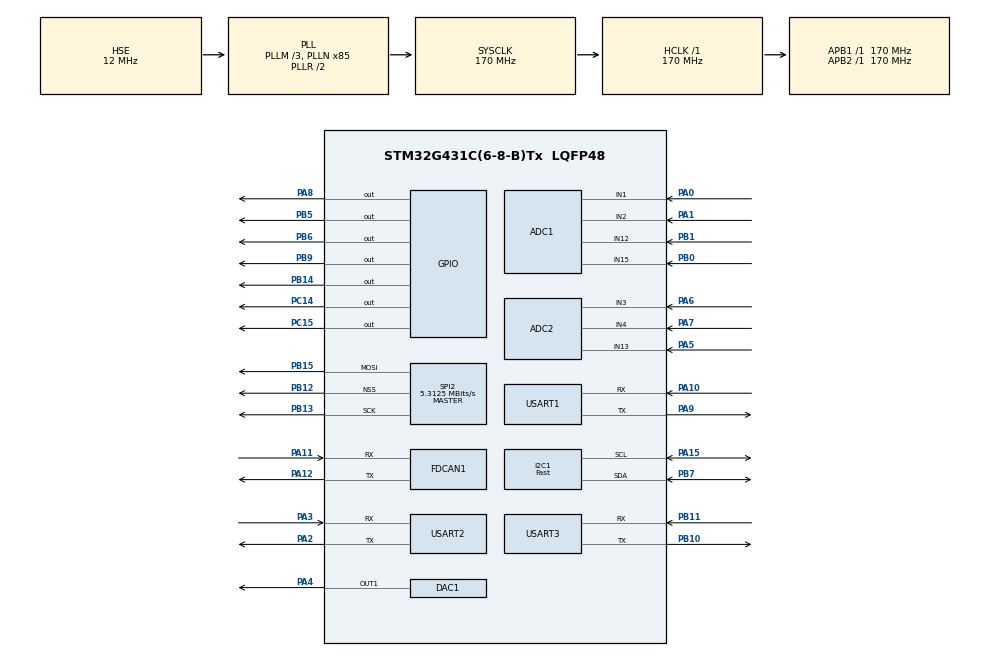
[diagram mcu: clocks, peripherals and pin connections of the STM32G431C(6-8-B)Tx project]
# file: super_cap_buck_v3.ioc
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ADC1.Channel-0\#ChannelRegularConversion=ADC_CHANNEL_1
ADC1.Channel-1\#ChannelRegularConversion=ADC_CHANNEL_2
ADC1.Channel-2\#ChannelRegularConversion=ADC_CHANNEL_12
ADC1.Channel-3\#ChannelRegularConversion=ADC_CHANNEL_15
ADC1.Channel-4\#ChannelRegularConversion=ADC_CHANNEL_TEMPSENSOR_ADC1
ADC1.ClockPrescaler=ADC_CLOCK_ASYNC_DIV6
ADC1.ContinuousConvMode=ENABLE
ADC1.DMAContinuousRequests=ENABLE
ADC1.DiscontinuousConvMode=DISABLE
ADC1.EOCSelection=ADC_EOC_SEQ_CONV
ADC1.EnableInjectedConversion=DISABLE
ADC1.GainCompensation=0
ADC1.NbrOfConversion=5
ADC1.NbrOfConversionFlag=1
ADC1.OffsetNumber-0\#ChannelRegularConversion=ADC_OFFSET_NONE
ADC1.OffsetNumber-1\#ChannelRegularConversion=ADC_OFFSET_NONE
ADC1.OffsetNumber-2\#ChannelRegularConversion=ADC_OFFSET_NONE
ADC1.OffsetNumber-3\#ChannelRegularConversion=ADC_OFFSET_NONE
ADC1.OffsetNumber-4\#ChannelRegularConversion=ADC_OFFSET_NONE
ADC1.OversamplingMode=ENABLE
ADC1.Rank-0\#ChannelRegularConversion=1
ADC1.Rank-1\#ChannelRegularConversion=2
ADC1.Rank-2\#ChannelRegularConversion=3
ADC1.Rank-3\#ChannelRegularConversion=4
ADC1.Rank-4\#ChannelRegularConversion=5
ADC1.Ratio=ADC_OVERSAMPLING_RATIO_256
ADC1.RightBitShift=ADC_RIGHTBITSHIFT_4
ADC1.SamplingTime-0\#ChannelRegularConversion=ADC_SAMPLETIME_3CYCLES_5
ADC1.SamplingTime-1\#ChannelRegularConversion=ADC_SAMPLETIME_3CYCLES_5
ADC1.SamplingTime-2\#ChannelRegularConversion=ADC_SAMPLETIME_3CYCLES_5
ADC1.SamplingTime-3\#ChannelRegularConversion=ADC_SAMPLETIME_3CYCLES_5
ADC1.SamplingTime-4\#ChannelRegularConversion=ADC_SAMPLETIME_92CYCLES_5
ADC1.master=1
ADC2.Channel-0\#ChannelRegularConversion=ADC_CHANNEL_13
ADC2.Channel-1\#ChannelRegularConversion=ADC_CHANNEL_3
ADC2.Channel-2\#ChannelRegularConversion=ADC_CHANNEL_4
ADC2.ClockPrescaler=ADC_CLOCK_ASYNC_DIV6
ADC2.ContinuousConvMode=ENABLE
ADC2.DMAContinuousRequests=ENABLE
ADC2.EOCSelection=ADC_EOC_SEQ_CONV
ADC2.EnableAnalogWatchDog1=false
ADC2.EnableInjectedConversion=DISABLE
ADC2.NbrOfConversion=3
ADC2.NbrOfConversionFlag=1
ADC2.OffsetNumber-0\#ChannelRegularConversion=ADC_OFFSET_NONE
ADC2.OffsetNumber-1\#ChannelRegularConversion=ADC_OFFSET_NONE
ADC2.OffsetNumber-2\#ChannelRegularConversion=ADC_OFFSET_NONE
ADC2.OversamplingMode=ENABLE
ADC2.Rank-0\#ChannelRegularConversion=1
ADC2.Rank-1\#ChannelRegularConversion=2
ADC2.Rank-2\#ChannelRegularConversion=3
ADC2.Ratio=ADC_OVERSAMPLING_RATIO_256
ADC2.RightBitShift=ADC_RIGHTBITSHIFT_4
ADC2.SamplingTime-0\#ChannelRegularConversion=ADC_SAMPLETIME_3CYCLES_5
ADC2.SamplingTime-1\#ChannelRegularConversion=ADC_SAMPLETIME_3CYCLES_5
ADC2.SamplingTime-2\#ChannelRegularConversion=ADC_SAMPLETIME_3CYCLES_5
DAC1.DAC_Trigger_OUT1-DAC_OUT1=DAC_TRIGGER_SOFTWARE
Dma.ADC1.0.Direction=DMA_PERIPH_TO_MEMORY
Dma.ADC1.0.EventEnable=DISABLE
Dma.ADC1.0.Instance=DMA1_Channel1
Dma.ADC1.0.MemDataAlignment=DMA_MDATAALIGN_WORD
Dma.ADC1.0.MemInc=DMA_MINC_ENABLE
Dma.ADC1.0.Mode=DMA_CIRCULAR
Dma.ADC1.0.PeriphDataAlignment=DMA_PDATAALIGN_WORD
Dma.ADC1.0.PeriphInc=DMA_PINC_DISABLE
Dma.ADC1.0.Polarity=HAL_DMAMUX_REQ_GEN_RISING
Dma.ADC1.0.Priority=DMA_PRIORITY_HIGH
Dma.ADC1.0.RequestNumber=1
Dma.ADC1.0.SignalID=NONE
Dma.ADC1.0.SyncEnable=DISABLE
Dma.ADC1.0.SyncPolarity=HAL_DMAMUX_SYNC_NO_EVENT
Dma.ADC1.0.SyncRequestNumber=1
Dma.ADC1.0.SyncSignalID=NONE
Dma.ADC2.1.Direction=DMA_PERIPH_TO_MEMORY
Dma.ADC2.1.EventEnable=DISABLE
Dma.ADC2.1.Instance=DMA1_Channel3
Dma.ADC2.1.MemDataAlignment=DMA_MDATAALIGN_WORD
Dma.ADC2.1.MemInc=DMA_MINC_ENABLE
Dma.ADC2.1.Mode=DMA_CIRCULAR
Dma.ADC2.1.PeriphDataAlignment=DMA_PDATAALIGN_WORD
Dma.ADC2.1.PeriphInc=DMA_PINC_DISABLE
Dma.ADC2.1.Polarity=HAL_DMAMUX_REQ_GEN_RISING
Dma.ADC2.1.Priority=DMA_PRIORITY_HIGH
Dma.ADC2.1.RequestNumber=1
Dma.ADC2.1.SignalID=NONE
Dma.ADC2.1.SyncEnable=DISABLE
Dma.ADC2.1.SyncPolarity=HAL_DMAMUX_SYNC_NO_EVENT
Dma.ADC2.1.SyncRequestNumber=1
Dma.ADC2.1.SyncSignalID=NONE
Dma.Request0=ADC1
Dma.Request1=ADC2
Dma.Request2=USART1_RX
Dma.Request3=USART2_RX
Dma.Request4=USART3_RX
Dma.USART1_RX.2.Direction=DMA_PERIPH_TO_MEMORY
Dma.USART1_RX.2.EventEnable=DISABLE
Dma.USART1_RX.2.Instance=DMA1_Channel2
Dma.USART1_RX.2.MemDataAlignment=DMA_MDATAALIGN_BYTE
Dma.USART1_RX.2.MemInc=DMA_MINC_ENABLE
Dma.USART1_RX.2.Mode=DMA_CIRCULAR
Dma.USART1_RX.2.PeriphDataAlignment=DMA_PDATAALIGN_BYTE
Dma.USART1_RX.2.PeriphInc=DMA_PINC_DISABLE
Dma.USART1_RX.2.Polarity=HAL_DMAMUX_REQ_GEN_RISING
Dma.USART1_RX.2.Priority=DMA_PRIORITY_HIGH
Dma.USART1_RX.2.RequestNumber=1
Dma.USART1_RX.2.SignalID=NONE
Dma.USART1_RX.2.SyncEnable=DISABLE
Dma.USART1_RX.2.SyncPolarity=HAL_DMAMUX_SYNC_NO_EVENT
Dma.USART1_RX.2.SyncRequestNumber=1
Dma.USART1_RX.2.SyncSignalID=NONE
Dma.USART2_RX.3.Direction=DMA_PERIPH_TO_MEMORY
Dma.USART2_RX.3.EventEnable=DISABLE
Dma.USART2_RX.3.Instance=DMA1_Channel4
Dma.USART2_RX.3.MemDataAlignment=DMA_MDATAALIGN_BYTE
Dma.USART2_RX.3.MemInc=DMA_MINC_ENABLE
Dma.USART2_RX.3.Mode=DMA_CIRCULAR
Dma.USART2_RX.3.PeriphDataAlignment=DMA_PDATAALIGN_BYTE
Dma.USART2_RX.3.PeriphInc=DMA_PINC_DISABLE
Dma.USART2_RX.3.Polarity=HAL_DMAMUX_REQ_GEN_RISING
Dma.USART2_RX.3.Priority=DMA_PRIORITY_LOW
Dma.USART2_RX.3.RequestNumber=1
Dma.USART2_RX.3.SignalID=NONE
Dma.USART2_RX.3.SyncEnable=DISABLE
Dma.USART2_RX.3.SyncPolarity=HAL_DMAMUX_SYNC_NO_EVENT
Dma.USART2_RX.3.SyncRequestNumber=1
Dma.USART2_RX.3.SyncSignalID=NONE
Dma.USART3_RX.4.Direction=DMA_PERIPH_TO_MEMORY
Dma.USART3_RX.4.EventEnable=DISABLE
Dma.USART3_RX.4.Instance=DMA1_Channel5
Dma.USART3_RX.4.MemDataAlignment=DMA_MDATAALIGN_BYTE
Dma.USART3_RX.4.MemInc=DMA_MINC_ENABLE
Dma.USART3_RX.4.Mode=DMA_CIRCULAR
Dma.USART3_RX.4.PeriphDataAlignment=DMA_PDATAALIGN_BYTE
Dma.USART3_RX.4.PeriphInc=DMA_PINC_DISABLE
Dma.USART3_RX.4.Polarity=HAL_DMAMUX_REQ_GEN_RISING
Dma.USART3_RX.4.Priority=DMA_PRIORITY_LOW
Dma.USART3_RX.4.RequestNumber=1
Dma.USART3_RX.4.SignalID=NONE
Dma.USART3_RX.4.SyncEnable=DISABLE
Dma.USART3_RX.4.SyncPolarity=HAL_DMAMUX_SYNC_NO_EVENT
Dma.USART3_RX.4.SyncRequestNumber=1
Dma.USART3_RX.4.SyncSignalID=NONE
FDCAN1.AutoRetransmission=ENABLE
FDCAN1.ClockDivider=FDCAN_CLOCK_DIV1
FDCAN1.DataPrescaler=17
FDCAN1.DataTimeSeg1=6
FDCAN1.DataTimeSeg2=3
FDCAN1.ExtFiltersNbr=8
FDCAN1.FrameFormat=FDCAN_FRAME_CLASSIC
FDCAN1.Mode=FDCAN_MODE_NORMAL
FDCAN1.NominalPrescaler=17
FDCAN1.NominalTimeSeg1=6
FDCAN1.NominalTimeSeg2=3
FDCAN1.ProtocolException=ENABLE
FDCAN1.StdFiltersNbr=8
FDCAN1.TransmitPause=ENABLE
FREERTOS.Tasks01=defaultTask,0,256,StartDefaultTask,Default,NULL,Dynamic,NULL,NULL;Ledshine,-3,128,Task_Ledshine,As weak,NULL,Dynamic,NULL,NULL;CapBuckControl,3,512,Task_CapBuckControl,As weak,NULL,Dynamic,NULL,NULL;Boost_Control,-3,256,Task_Boost_Control,As weak,NULL,Dynamic,NULL,NULL;Ref_Power_Limit,-3,256,Task_Ref_Power_Limit,As weak,NULL,Dynamic,NULL,NULL;Power_Control,2,256,Task_Power_Control,As weak,NULL,Dynamic,NULL,NULL;Feed_Dog,0,128,Task_Feed_Dog,As weak,NULL,Dynamic,NULL,NULL;Error_Detect,-3,256,Task_Error_Detect,As weak,NULL,Dynamic,NULL,NULL;BlueTooth,0,512,Task_BlueTooth,As weak,NULL,Dynamic,NULL,NULL;Oled_Show,0,256,Task_Oled_Show,As weak,NULL,Dynamic,NULL,NULL
FREERTOS.configENABLE_FPU=0
FREERTOS.configTOTAL_HEAP_SIZE=20000
I2C1.I2C_Speed_Mode=I2C_Fast
I2C1.Timing=0x10802D9B
Mcu.Family=STM32G4
Mcu.Name=STM32G431C(6-8-B)Tx
Mcu.Package=LQFP48
NVIC.ADC1_2_IRQn=true\:5\:0\:false\:false\:true\:true\:true\:true
NVIC.DMA1_Channel1_IRQn=true\:5\:0\:true\:false\:true\:true\:true\:true
NVIC.DMA1_Channel2_IRQn=true\:5\:0\:false\:false\:true\:true\:false\:true
NVIC.DMA1_Channel3_IRQn=true\:5\:0\:false\:false\:true\:true\:false\:true
NVIC.DMA1_Channel4_IRQn=true\:5\:0\:false\:false\:true\:true\:false\:true
NVIC.DMA1_Channel5_IRQn=true\:5\:0\:false\:false\:true\:true\:false\:true
NVIC.FDCAN1_IT0_IRQn=true\:5\:0\:false\:false\:true\:true\:true\:true
NVIC.PriorityGroup=NVIC_PRIORITYGROUP_4
NVIC.TIM1_BRK_TIM15_IRQn=true\:5\:0\:false\:false\:true\:true\:true\:true
NVIC.TIM1_TRG_COM_TIM17_IRQn=true\:15\:0\:true\:false\:true\:false\:false\:true
NVIC.TIM1_UP_TIM16_IRQn=true\:5\:0\:false\:false\:true\:true\:true\:true
NVIC.TIM2_IRQn=true\:5\:0\:false\:false\:true\:true\:true\:true
NVIC.TIM8_UP_IRQn=true\:5\:0\:false\:false\:true\:true\:true\:true
NVIC.TimeBase=TIM1_TRG_COM_TIM17_IRQn
NVIC.TimeBaseIP=TIM17
NVIC.USART1_IRQn=true\:5\:0\:false\:false\:true\:true\:true\:true
NVIC.USART2_IRQn=true\:5\:0\:false\:false\:true\:true\:true\:true
NVIC.USART3_IRQn=true\:5\:0\:false\:false\:true\:true\:true\:true
PA0.Mode=IN1-Single-Ended
PA0.Signal=ADC1_IN1
PA1.Mode=IN2-Single-Ended
PA1.Signal=ADC1_IN2
PA10.Mode=Asynchronous
PA10.Signal=USART1_RX
PA11.GPIO_FM8=SYSCFG_FASTMODEPLUS_PB8
PA11.GPIO_Speed=GPIO_SPEED_FREQ_VERY_HIGH
PA11.Mode=FDCAN_Activate
PA11.Signal=FDCAN1_RX
PA12.GPIO_FM9=SYSCFG_FASTMODEPLUS_PB9
PA12.GPIO_Speed=GPIO_SPEED_FREQ_VERY_HIGH
PA12.Mode=FDCAN_Activate
PA12.Signal=FDCAN1_TX
PA13.Mode=Serial_Wire
PA13.Signal=SYS_JTMS-SWDIO
PA14.Mode=Serial_Wire
PA14.Signal=SYS_JTCK-SWCLK
PA15.GPIO_Pu=GPIO_PULLUP
PA15.Mode=I2C
PA15.Signal=I2C1_SCL
PA2.Mode=Asynchronous
PA2.Signal=USART2_TX
PA3.Mode=Asynchronous
PA3.Signal=USART2_RX
PA4.Signal=COMP_DAC11_group
PA5.Mode=IN13-Single-Ended
PA5.Signal=ADC2_IN13
PA6.Mode=IN3-Single-Ended
PA6.Signal=ADC2_IN3
PA7.Mode=IN4-Single-Ended
PA7.Signal=ADC2_IN4
PA8.Signal=GPIO_Output
PA9.Mode=Asynchronous
PA9.Signal=USART1_TX
PB0.Mode=IN15-Single-Ended
PB0.Signal=ADC1_IN15
PB1.Mode=IN12-Single-Ended
PB1.Signal=ADC1_IN12
PB10.Mode=Asynchronous
PB10.Signal=USART3_TX
PB11.Mode=Asynchronous
PB11.Signal=USART3_RX
PB12.Mode=NSS_Signal_Hard_Output
PB12.Signal=SPI2_NSS
PB13.Mode=TX_Only_Simplex_Unidirect_Master
PB13.Signal=SPI2_SCK
PB14.Signal=GPIO_Output
PB15.Mode=TX_Only_Simplex_Unidirect_Master
PB15.Signal=SPI2_MOSI
PB5.Signal=GPIO_Output
PB6.Signal=GPIO_Output
PB7.GPIO_Pu=GPIO_PULLUP
PB7.Mode=I2C
PB7.Signal=I2C1_SDA
PB9.Signal=GPIO_Output
PC14-OSC32_IN.Signal=GPIO_Output
PC15-OSC32_OUT.Signal=GPIO_Output
PF0-OSC_IN.Mode=HSE-External-Oscillator
PF0-OSC_IN.Signal=RCC_OSC_IN
PF1-OSC_OUT.Mode=HSE-External-Oscillator
PF1-OSC_OUT.Signal=RCC_OSC_OUT
ProjectManager.HeapSize=0x1000
ProjectManager.StackSize=0x1000
ProjectManager.TargetToolchain=MDK-ARM V5.32
RCC.ADC12Freq_Value=170000000
RCC.AHBFreq_Value=170000000
RCC.APB1Freq_Value=170000000
RCC.APB1TimFreq_Value=170000000
RCC.APB2Freq_Value=170000000
RCC.APB2TimFreq_Value=170000000
RCC.CK48CLockSelection=RCC_USBCLKSOURCE_HSI48
RCC.CortexFreq_Value=170000000
RCC.EXTERNAL_CLOCK_VALUE=12288000
RCC.HCLKFreq_Value=170000000
RCC.HSE_VALUE=12000000
RCC.HSI48_VALUE=48000000
RCC.HSI_VALUE=16000000
RCC.LSE_VALUE=32768
RCC.PLLM=RCC_PLLM_DIV3
RCC.PLLN=85
RCC.PLLQ=RCC_PLLQ_DIV4
RCC.PLLSourceVirtual=RCC_PLLSOURCE_HSE
RCC.SYSCLKFreq_VALUE=170000000
RCC.SYSCLKSource=RCC_SYSCLKSOURCE_PLLCLK
RCC.USBFreq_Value=48000000
RCC.VCOOutputFreq_Value=340000000
SH.COMP_DAC11_group.0=DAC1_OUT1,DAC_OUT1
SPI2.BaudRatePrescaler=SPI_BAUDRATEPRESCALER_32
SPI2.CalculateBaudRate=5.3125 MBits/s
SPI2.DataSize=SPI_DATASIZE_10BIT
SPI2.Direction=SPI_DIRECTION_2LINES
SPI2.Mode=SPI_MODE_MASTER
SPI2.VirtualNSS=VM_NSSHARD
SPI2.VirtualType=VM_MASTER
TIM1.PeriodNoDither=1000-1
TIM1.Prescaler=170-1
TIM15.PeriodNoDither=100-1
TIM15.Prescaler=170-1
TIM16.PeriodNoDither=100-1
TIM16.Prescaler=170-1
TIM2.PeriodNoDither=200-1
TIM2.Prescaler=170-1
TIM2.TIM_MasterOutputTrigger=TIM_TRGO_UPDATE
TIM2.TIM_MasterSlaveMode=TIM_MASTERSLAVEMODE_ENABLE
TIM8.PeriodNoDither=10000-1
TIM8.Prescaler=170-1
USART1.VirtualMode-Asynchronous=VM_ASYNC
USART2.VirtualMode-Asynchronous=VM_ASYNC
USART3.VirtualMode-Asynchronous=VM_ASYNC
VP_ADC1_TempSens_Input.Mode=IN-TempSens
VP_FREERTOS_VS_CMSIS_V1.Mode=CMSIS_V1
VP_SYS_VS_DBSignals.Mode=DisableDeadBatterySignals
VP_SYS_VS_tim17.Mode=TIM17
VP_SYS_V_VREFBUF.Mode=ExternalMode
VP_TIM15_VS_ClockSourceINT.Mode=Internal
VP_TIM16_VS_ClockSourceINT.Mode=Enable_Timer
VP_TIM1_VS_ClockSourceINT.Mode=Internal
VP_TIM2_VS_ClockSourceINT.Mode=Internal
VP_TIM8_VS_ClockSourceINT.Mode=Internal
board=custom

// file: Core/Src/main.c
/* USER CODE BEGIN Header */
/**
  ******************************************************************************
  * @file           : main.c
  * @brief          : Main program body
  ******************************************************************************
  * @attention
  *
  * <h2><center>&copy; Copyright (c) 2022 STMicroelectronics.
  * All rights reserved.</center></h2>
  *
  * This software component is licensed by ST under Ultimate Liberty license
  * SLA0044, the "License"; You may not use this file except in compliance with
  * the License. You may obtain a copy of the License at:
  *                             www.st.com/SLA0044
  *
  ******************************************************************************
  */
/* USER CODE END Header */
#include "main.h"
#include "cmsis_os.h"
#include "adc.h"
#include "dac.h"
#include "dma.h"
#include "fdcan.h"
#include "i2c.h"
#include "spi.h"
#include "tim.h"
#include "usart.h"
#include "gpio.h"

/* USER CODE BEGIN Includes */
#include"Cap_Control.h"
#include"dac_util.h"
#include"remote_Periph.h"
#include"adc_util.h"
#include "Decoder.h"
#include "AD8402_Periph.h"

/* USER CODE END Includes */

void SystemClock_Config(void);
void MX_FREERTOS_Init(void);

int main(void)
{

  /* MCU Configuration--------------------------------------------------------*/

  /* Reset of all peripherals, Initializes the Flash interface and the Systick. */
  HAL_Init();

  /* Configure the system clock */
  SystemClock_Config();

  /* USER CODE BEGIN SysInit */
  MX_DMA_Init();
  /* USER CODE END SysInit */

  /* Initialize all configured peripherals */
  MX_GPIO_Init();
  MX_ADC1_Init();
  MX_ADC2_Init();
  MX_FDCAN1_Init();
  MX_I2C1_Init();
  MX_USART1_UART_Init();
  MX_USART2_UART_Init();
  MX_USART3_UART_Init();
  MX_DMA_Init();
  MX_TIM16_Init();
  MX_TIM15_Init();
  MX_TIM1_Init();
  MX_SPI2_Init();
  MX_DAC1_Init();
  MX_TIM8_Init();
  MX_TIM2_Init();
  /* USER CODE BEGIN 2 */
	Cap_Control_Change_Cap_PowerPath();
 // HAL_TIM_Base_Start_IT(&htim8);
	//HAL_IWDG_Refresh(&hiwdg);

  /* USER CODE END 2 */

  /* Call init function for freertos objects (in freertos.c) */
  MX_FREERTOS_Init();
  /* Start scheduler */
  osKernelStart();

  /* We should never get here as control is now taken by the scheduler */
  /* Infinite loop */
  while (1)
  {

  }
}

void SystemClock_Config(void)
{
  RCC_OscInitTypeDef RCC_OscInitStruct = {0};
  RCC_ClkInitTypeDef RCC_ClkInitStruct = {0};

  /** Configure the main internal regulator output voltage
  */
  HAL_PWREx_ControlVoltageScaling(PWR_REGULATOR_VOLTAGE_SCALE1_BOOST);
  /** Initializes the RCC Oscillators according to the specified parameters
  * in the RCC_OscInitTypeDef structure.
  */
  RCC_OscInitStruct.OscillatorType = RCC_OSCILLATORTYPE_HSE;
  RCC_OscInitStruct.HSEState = RCC_HSE_ON;
  RCC_OscInitStruct.PLL.PLLState = RCC_PLL_ON;
  RCC_OscInitStruct.PLL.PLLSource = RCC_PLLSOURCE_HSE;
  RCC_OscInitStruct.PLL.PLLM = RCC_PLLM_DIV3;
  RCC_OscInitStruct.PLL.PLLN = 85;
  RCC_OscInitStruct.PLL.PLLP = RCC_PLLP_DIV2;
  RCC_OscInitStruct.PLL.PLLQ = RCC_PLLQ_DIV4;
  RCC_OscInitStruct.PLL.PLLR = RCC_PLLR_DIV2;
  if (HAL_RCC_OscConfig(&RCC_OscInitStruct) != HAL_OK)
  {
    Error_Handler();
  }
  /** Initializes the CPU, AHB and APB buses clocks
  */
  RCC_ClkInitStruct.ClockType = RCC_CLOCKTYPE_HCLK|RCC_CLOCKTYPE_SYSCLK
                              |RCC_CLOCKTYPE_PCLK1|RCC_CLOCKTYPE_PCLK2;
  RCC_ClkInitStruct.SYSCLKSource = RCC_SYSCLKSOURCE_PLLCLK;
  RCC_ClkInitStruct.AHBCLKDivider = RCC_SYSCLK_DIV1;
  RCC_ClkInitStruct.APB1CLKDivider = RCC_HCLK_DIV1;
  RCC_ClkInitStruct.APB2CLKDivider = RCC_HCLK_DIV1;

  if (HAL_RCC_ClockConfig(&RCC_ClkInitStruct, FLASH_LATENCY_4) != HAL_OK)
  {
    Error_Handler();
  }
}

void HAL_TIM_PeriodElapsedCallback(TIM_HandleTypeDef *htim)
{
  if (htim->Instance == TIM17) {
    HAL_IncTick();
  }
  /* USER CODE BEGIN Callback 1 */
	else if (htim == &htim15)
  {
   Cap_Control_Backflush();

}
	else if(htim == &htim16)
	{
			Buck_Control_Pid_Clac();

	}
	else if(htim == &htim8) {
	//	HAL_IWDG_Refresh(&hiwdg);
	}

  /* USER CODE END Callback 1 */
}

void Error_Handler(void)
{
  __disable_irq();
  while (1)
  {
  }
}

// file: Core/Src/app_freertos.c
/* USER CODE BEGIN Header */
/**
  ******************************************************************************
  * File Name          : app_freertos.c
  * Description        : Code for freertos applications
  ******************************************************************************
  * @attention
  *
  * <h2><center>&copy; Copyright (c) 2022 STMicroelectronics.
  * All rights reserved.</center></h2>
  *
  * This software component is licensed by ST under Ultimate Liberty license
  * SLA0044, the "License"; You may not use this file except in compliance with
  * the License. You may obtain a copy of the License at:
  *                             www.st.com/SLA0044
  *
  ******************************************************************************
  */
/* USER CODE END Header */

#include "FreeRTOS.h"
#include "task.h"
#include "main.h"
#include "cmsis_os.h"

osThreadId defaultTaskHandle;
osThreadId LedshineHandle;
osThreadId CapBuckControlHandle;
osThreadId Boost_ControlHandle;
osThreadId Ref_Power_LimitHandle;
osThreadId Power_ControlHandle;
osThreadId Feed_DogHandle;
osThreadId Error_DetectHandle;
osThreadId BlueToothHandle;
osThreadId Oled_ShowHandle;

void StartDefaultTask(void const * argument);
void Task_Ledshine(void const * argument);
void Task_CapBuckControl(void const * argument);
void Task_Boost_Control(void const * argument);
void Task_Ref_Power_Limit(void const * argument);
void Task_Power_Control(void const * argument);
void Task_Feed_Dog(void const * argument);
void Task_Error_Detect(void const * argument);
void Task_BlueTooth(void const * argument);
void Task_Oled_Show(void const * argument);

void MX_FREERTOS_Init(void); /* (MISRA C 2004 rule 8.1) */

void MX_FREERTOS_Init(void) {

  /* Create the thread(s) */
  /* definition and creation of defaultTask */
  osThreadDef(defaultTask, StartDefaultTask, osPriorityNormal, 0, 256);
  defaultTaskHandle = osThreadCreate(osThread(defaultTask), NULL);

  /* definition and creation of Ledshine */
  osThreadDef(Ledshine, Task_Ledshine, osPriorityIdle, 0, 128);
  LedshineHandle = osThreadCreate(osThread(Ledshine), NULL);

  /* definition and creation of CapBuckControl */
  osThreadDef(CapBuckControl, Task_CapBuckControl, osPriorityRealtime, 0, 512);
  CapBuckControlHandle = osThreadCreate(osThread(CapBuckControl), NULL);

  /* definition and creation of Boost_Control */
  osThreadDef(Boost_Control, Task_Boost_Control, osPriorityIdle, 0, 256);
  Boost_ControlHandle = osThreadCreate(osThread(Boost_Control), NULL);

  /* definition and creation of Ref_Power_Limit */
  osThreadDef(Ref_Power_Limit, Task_Ref_Power_Limit, osPriorityIdle, 0, 256);
  Ref_Power_LimitHandle = osThreadCreate(osThread(Ref_Power_Limit), NULL);

  /* definition and creation of Power_Control */
  osThreadDef(Power_Control, Task_Power_Control, osPriorityHigh, 0, 256);
  Power_ControlHandle = osThreadCreate(osThread(Power_Control), NULL);

  /* definition and creation of Feed_Dog */
  osThreadDef(Feed_Dog, Task_Feed_Dog, osPriorityNormal, 0, 128);
  Feed_DogHandle = osThreadCreate(osThread(Feed_Dog), NULL);

  /* definition and creation of Error_Detect */
  osThreadDef(Error_Detect, Task_Error_Detect, osPriorityIdle, 0, 256);
  Error_DetectHandle = osThreadCreate(osThread(Error_Detect), NULL);

  /* definition and creation of BlueTooth */
  osThreadDef(BlueTooth, Task_BlueTooth, osPriorityNormal, 0, 512);
  BlueToothHandle = osThreadCreate(osThread(BlueTooth), NULL);

  /* definition and creation of Oled_Show */
  osThreadDef(Oled_Show, Task_Oled_Show, osPriorityNormal, 0, 256);
  Oled_ShowHandle = osThreadCreate(osThread(Oled_Show), NULL);

}

void StartDefaultTask(void const * argument)
{
  for(;;)
  {
    osDelay(1);
  }
}

__weak void Task_Ledshine(void const * argument)
{
  for(;;)
  {
    osDelay(1);
  }
}

__weak void Task_CapBuckControl(void const * argument)
{
  for(;;)
  {
    osDelay(1);
  }
}

__weak void Task_Boost_Control(void const * argument)
{
  for(;;)
  {
    osDelay(1);
  }
}

__weak void Task_Ref_Power_Limit(void const * argument)
{
  for(;;)
  {
    osDelay(1);
  }
}

__weak void Task_Power_Control(void const * argument)
{
  for(;;)
  {
    osDelay(1);
  }
}

__weak void Task_Feed_Dog(void const * argument)
{
  for(;;)
  {
    osDelay(1);
  }
}

__weak void Task_Error_Detect(void const * argument)
{
  for(;;)
  {
    osDelay(1);
  }
}

__weak void Task_BlueTooth(void const * argument)
{
  for(;;)
  {
    osDelay(1);
  }
}

__weak void Task_Oled_Show(void const * argument)
{
  for(;;)
  {
    osDelay(1);
  }
}
